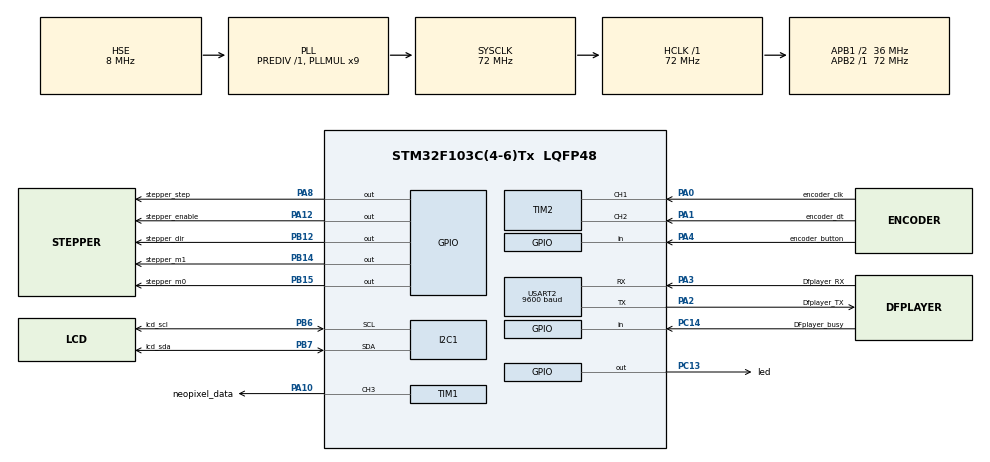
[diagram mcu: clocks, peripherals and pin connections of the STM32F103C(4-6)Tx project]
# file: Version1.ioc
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Dma.Request0=TIM1_CH3
Dma.TIM1_CH3.0.Direction=DMA_MEMORY_TO_PERIPH
Dma.TIM1_CH3.0.Instance=DMA1_Channel6
Dma.TIM1_CH3.0.MemDataAlignment=DMA_MDATAALIGN_WORD
Dma.TIM1_CH3.0.MemInc=DMA_MINC_ENABLE
Dma.TIM1_CH3.0.Mode=DMA_CIRCULAR
Dma.TIM1_CH3.0.PeriphDataAlignment=DMA_PDATAALIGN_WORD
Dma.TIM1_CH3.0.PeriphInc=DMA_PINC_DISABLE
Dma.TIM1_CH3.0.Priority=DMA_PRIORITY_LOW
Mcu.Family=STM32F1
Mcu.Name=STM32F103C(4-6)Tx
Mcu.Package=LQFP48
NVIC.DMA1_Channel6_IRQn=true\:0\:0\:false\:false\:true\:false\:true\:true
NVIC.PriorityGroup=NVIC_PRIORITYGROUP_4
NVIC.TIM2_IRQn=true\:0\:0\:false\:false\:true\:true\:true\:true
NVIC.TIM3_IRQn=true\:0\:0\:false\:false\:true\:true\:true\:true
NVIC.USART2_IRQn=true\:0\:0\:false\:false\:true\:true\:true\:true
PA0-WKUP.GPIO_Label=encoder_clk
PA0-WKUP.GPIO_PuPd=GPIO_NOPULL
PA0-WKUP.Signal=S_TIM2_CH1_ETR
PA1.GPIO_Label=encoder_dt
PA1.GPIO_PuPd=GPIO_NOPULL
PA1.Signal=S_TIM2_CH2
PA10.GPIO_Label=neopixel_data
PA10.GPIO_Speed=GPIO_SPEED_FREQ_HIGH
PA10.Signal=S_TIM1_CH3
PA12.GPIO_Label=stepper_enable
PA12.Signal=GPIO_Output
PA2.GPIO_Label=Dfplayer_TX
PA2.Mode=Asynchronous
PA2.Signal=USART2_TX
PA3.GPIO_Label=Dfplayer_RX
PA3.Mode=Asynchronous
PA3.Signal=USART2_RX
PA4.GPIO_Label=encoder_button
PA4.GPIO_PuPd=GPIO_PULLUP
PA4.Signal=GPIO_Input
PA8.GPIO_Label=stepper_step
PA8.GPIO_Speed=GPIO_SPEED_FREQ_HIGH
PA8.Signal=GPIO_Output
PB12.GPIO_Label=stepper_dir
PB12.Signal=GPIO_Output
PB14.GPIO_Label=stepper_m1
PB14.Signal=GPIO_Output
PB15.GPIO_Label=stepper_m0
PB15.Signal=GPIO_Output
PB6.GPIO_Label=lcd_scl
PB6.GPIO_Pu=GPIO_PULLUP
PB6.Mode=I2C
PB6.Signal=I2C1_SCL
PB7.GPIO_Label=lcd_sda
PB7.GPIO_Pu=GPIO_PULLUP
PB7.Mode=I2C
PB7.Signal=I2C1_SDA
PC13-TAMPER-RTC.GPIO_Label=led
PC13-TAMPER-RTC.Signal=GPIO_Output
PC14-OSC32_IN.GPIO_Label=DFplayer_busy
PC14-OSC32_IN.Signal=GPIO_Input
PD0-OSC_IN.Mode=HSE-External-Oscillator
PD0-OSC_IN.Signal=RCC_OSC_IN
PD1-OSC_OUT.Mode=HSE-External-Oscillator
PD1-OSC_OUT.Signal=RCC_OSC_OUT
ProjectManager.HeapSize=0x200
ProjectManager.StackSize=0x400
ProjectManager.TargetToolchain=STM32CubeIDE
RCC.AHBFreq_Value=72000000
RCC.APB1CLKDivider=RCC_HCLK_DIV2
RCC.APB1Freq_Value=36000000
RCC.APB1TimFreq_Value=72000000
RCC.APB2Freq_Value=72000000
RCC.APB2TimFreq_Value=72000000
RCC.HCLKFreq_Value=72000000
RCC.PLLMUL=RCC_PLL_MUL9
RCC.PLLSourceVirtual=RCC_PLLSOURCE_HSE
RCC.SYSCLKFreq_VALUE=72000000
RCC.SYSCLKSource=RCC_SYSCLKSOURCE_PLLCLK
RCC.USBFreq_Value=72000000
SH.S_TIM1_CH3.0=TIM1_CH3,PWM Generation3 CH3
SH.S_TIM2_CH1_ETR.0=TIM2_CH1,Encoder_Interface
SH.S_TIM2_CH2.0=TIM2_CH2,Encoder_Interface
TIM1.AutoReloadPreload=TIM_AUTORELOAD_PRELOAD_DISABLE
TIM1.Channel-PWM\ Generation3\ CH3=TIM_CHANNEL_3
TIM1.Period=65535
TIM1.Prescaler=0
TIM2.AutoReloadPreload=TIM_AUTORELOAD_PRELOAD_ENABLE
TIM2.CounterMode=TIM_COUNTERMODE_UP
TIM2.EncoderMode=TIM_ENCODERMODE_TI12
TIM2.IC1Filter=10
TIM2.IC1Polarity=TIM_ICPOLARITY_RISING
TIM2.IC2Filter=10
TIM2.IC2Polarity=TIM_ICPOLARITY_FALLING
TIM3.AutoReloadPreload=TIM_AUTORELOAD_PRELOAD_DISABLE
TIM3.Period=7199
TIM3.Prescaler=0
USART2.BaudRate=9600
USART2.VirtualMode=VM_ASYNC
VP_TIM1_VS_ClockSourceINT.Mode=Internal
VP_TIM3_VS_ClockSourceINT.Mode=Internal
board=custom

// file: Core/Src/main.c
/* USER CODE BEGIN Header */
/**
  ******************************************************************************
  * @file           : main.c
  * @brief          : Main program body
  ******************************************************************************
  * @attention
  *
  * Copyright (c) 2022 STMicroelectronics.
  * All rights reserved.
  *
  * This software is licensed under terms that can be found in the LICENSE file
  * in the root directory of this software component.
  * If no LICENSE file comes with this software, it is provided AS-IS.
  *
  ******************************************************************************
  */
/* USER CODE END Header */
#include "main.h"
#include "dma.h"
#include "i2c.h"
#include "tim.h"
#include "usart.h"
#include "gpio.h"

void SystemClock_Config(void);

int main(void)
{

  /* MCU Configuration--------------------------------------------------------*/

  /* Reset of all peripherals, Initializes the Flash interface and the Systick. */
  HAL_Init();

  /* Configure the system clock */
  SystemClock_Config();

  /* Initialize all configured peripherals */
  MX_GPIO_Init();
  MX_DMA_Init();
  MX_I2C1_Init();
  MX_USART2_UART_Init();
  MX_TIM1_Init();
  MX_TIM2_Init();
  MX_TIM3_Init();
  /* USER CODE BEGIN 2 */
  HAL_TIM_Base_Start_IT(&htim3);
  HAL_TIM_Encoder_Start(&htim2, TIM_CHANNEL_ALL);
  HAL_TIM_Base_Start_IT(&htim2);

  logic();
  /* USER CODE END 2 */

  /* Infinite loop */
  while (1)
  {

  }
}

void SystemClock_Config(void)
{
  RCC_OscInitTypeDef RCC_OscInitStruct = {0};
  RCC_ClkInitTypeDef RCC_ClkInitStruct = {0};

  /** Initializes the RCC Oscillators according to the specified parameters
  * in the RCC_OscInitTypeDef structure.
  */
  RCC_OscInitStruct.OscillatorType = RCC_OSCILLATORTYPE_HSE;
  RCC_OscInitStruct.HSEState = RCC_HSE_ON;
  RCC_OscInitStruct.HSEPredivValue = RCC_HSE_PREDIV_DIV1;
  RCC_OscInitStruct.HSIState = RCC_HSI_ON;
  RCC_OscInitStruct.PLL.PLLState = RCC_PLL_ON;
  RCC_OscInitStruct.PLL.PLLSource = RCC_PLLSOURCE_HSE;
  RCC_OscInitStruct.PLL.PLLMUL = RCC_PLL_MUL9;
  if (HAL_RCC_OscConfig(&RCC_OscInitStruct) != HAL_OK)
  {
    Error_Handler();
  }

  /** Initializes the CPU, AHB and APB buses clocks
  */
  RCC_ClkInitStruct.ClockType = RCC_CLOCKTYPE_HCLK|RCC_CLOCKTYPE_SYSCLK
                              |RCC_CLOCKTYPE_PCLK1|RCC_CLOCKTYPE_PCLK2;
  RCC_ClkInitStruct.SYSCLKSource = RCC_SYSCLKSOURCE_PLLCLK;
  RCC_ClkInitStruct.AHBCLKDivider = RCC_SYSCLK_DIV1;
  RCC_ClkInitStruct.APB1CLKDivider = RCC_HCLK_DIV2;
  RCC_ClkInitStruct.APB2CLKDivider = RCC_HCLK_DIV1;

  if (HAL_RCC_ClockConfig(&RCC_ClkInitStruct, FLASH_LATENCY_2) != HAL_OK)
  {
    Error_Handler();
  }
}

/* USER CODE BEGIN 4 */
// Callback: timer has rolled over
void HAL_TIM_PeriodElapsedCallback(TIM_HandleTypeDef *htim)
{
  // Check which version of the timer triggered this callback and toggle LED
  if (htim == &htim3 )
  {
	  handleStepsInterrupt();

	  //HAL_GPIO_TogglePin(led_GPIO_Port, led_Pin);

  }
}

/* USER CODE END 4 */

void Error_Handler(void)
{
  __disable_irq();
  while (1)
  {
  }
}
